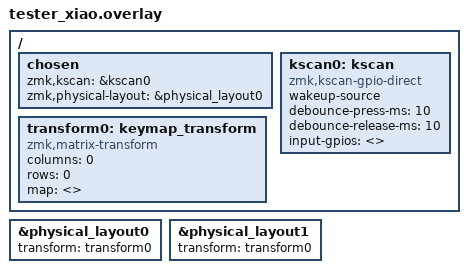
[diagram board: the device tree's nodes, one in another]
#include <dt-bindings/zmk/matrix_transform.h>
#include "tester_xiao-layouts.dtsi"

&physical_layout0 {
    transform = <&transform0>;
};

&physical_layout1 {
    transform = <&transform0>;
};

/ {
    chosen {
        zmk,kscan = &kscan0;
        zmk,physical-layout = &physical_layout0;
    };

    kscan0: kscan {
        compatible = "zmk,kscan-gpio-direct";
        wakeup-source;
        debounce-press-ms = <10>;
        debounce-release-ms = <10>;
        input-gpios = <>;
    };

    transform0: keymap_transform {
        compatible = "zmk,matrix-transform";
        columns = <0>;
        rows = <0>;
        map = <>;
    };
};
